# M2354 register map
File version: 1.0
Registers are 32-bit, read-write, reset 0x0 unless marked. A register's access mark holds for its fields unless they carry their own. Offsets are from the block's base; [hi:lo] are bit positions; {n}, {i} and the like mark numbered series; 'fields as' and 'values as' point back to an identical list.

## DPM_NS — SCU Register Map
Base 0x5002F600
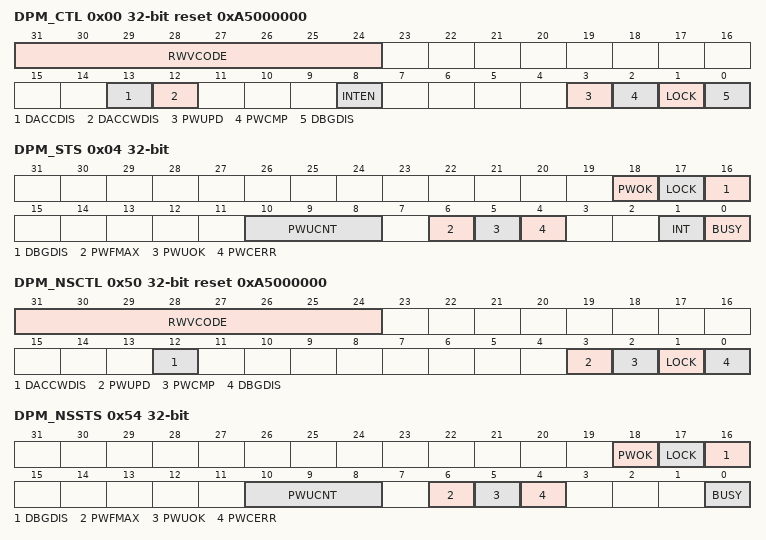
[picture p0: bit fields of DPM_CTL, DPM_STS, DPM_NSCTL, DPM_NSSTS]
0x00 DPM_CTL reset 0xA5000000 (reset mask 0xFFFFFFF0) — Secure DPM Control Register
  [31:24] RWVCODE — Write Verify Code and Read Verify Code. Read operation:
    90=The write verify code, 0x5A, is needed to do a valid write to DPM_CTL; 165=The read access for DPM_CTL is correct
  [13] DACCDIS — Debug Access Disable Bit. This bit disables the accessibility of external debugger to all DPM registers.
    0=External debugger can read/write DPM registers; 1=External debugger cannot read/write DPM registers
  [12] DACCWDIS — Secure DPM Debug Write Access Disable Bit. This bit disables the ability of external debugger to set Secure DPM registers for debug authentication.
    0=External debugger can set Secure DPM registers; 1=External debugger cannot set Secure DPM registers
  [8] INTEN — DPM Interrupt Enable Bit
    0=DPM interrupt function Enabled; 1=DPM interrupt function Disabled
  [3] PWUPD — Secure DPM Password Update Bit. Set to enter the process of updating Secure DPM password. Note 1: This bit should be set with PWCMP equal to 0. Note 2: This bit will be cleared after the update process is finished.
    0=No operation; 1=Update Secure DPM password
  [2] PWCMP — Secure DPM Password Compare Bit. Set to enter the process of compare Secure DPM password. Note: This bit will be cleared after the comparison process is finished.
    0=No operation; 1=Compare Secure DPM password
  [1] LOCK — Set Secure DPM Debug Lock Bit. When this bit is read as 0, it can be written to 1 to configure the Secure DPM LOCK bit (LOCKS). When written: Note: This bit can be set to 1 but cannot be cleared to 0.
    0=No operation; 1=Trigger the process to set LOCKS configuration bit
  [0] DBGDIS — Set Secure DPM Debug Disable Bit. When this bit is read as 0, it can be written to 1 to configure the Secure DPM DBGDIS bit (DBGDISS). When written: Note: This bit can be set to 1 but cannot be cleared to 0.
    0=No operation; 1=Trigger the process to set DBGDISS configuration bit
0x04 DPM_STS (reset mask 0xFFF0F0FF) — Secure DPM Status Register
  [18] PWOK ro — Secure Password OK Flag (Read Only). This bit indicates the Secure DPM password has been checked and is correct.
    0=The Secure DPM password has not been checked pass, yet; 1=The Secure DPM password has been checked pass since last cold reset
  [17] LOCK ro — Secure Debug Lock Flag (Read Only). This bit indicates the current value of LOCKS bit.
  [16] DBGDIS ro — Secure Debug Disable Flag (Read Only). This bit indicates the current value of DBGDISS bit. {PWOK, LOCK, DBGDIS} bits define the current state of DPM.
    0=DEFAULT state. LOCKED state; 1=CLOSE state; 5=OPEN state
  [10:8] PWUCNT ro — Secure DPM Password Updated Times (Read Only). This bit indicates how many times of secure password has been updated. The max value is 7. If PWUCNT reached the max value, Secure DPM password cannot be updated anymore.
  [6] PWFMAX ro — Secure DPM Password Fail Times Maximum Reached Flag (Read Only). This bit indicates if the fail times of comparing Secure DPM password reached max times.
    0=Max time has not reached and Secure DPM password comparison can be triggered; 1=Max time reached and Secure DPM password comparison cannot be processed anymore
  [5] PWUOK — Secure DPM Password Updated Flag. This bit indicates Secure DPM password has been updated successfully. When read: Note: This flag is write-one-clear.
    0=No successful updating process has happened; 1=There is at least one successful updating process since last clearing of this bit
  [4] PWCERR — Secure DPM Password Compared Error Flag. This bit indicates the result of Secure DPM password comparison. When read: Note: This flag is write-one-clear.
    0=The result of Secure DPM password is correct; 1=The result of Secure DPM password is incorrect
  [1] INT ro — DPM Interrupt Flag (Read Only). This bit indicates the interrupt is triggered. Note: This bit is cleared automatically when PWCERR flag in both DPM_STS and DPM_NSSTS are 0.
    0=Interrupt is not enabled or no password comparison flag is set; 1=Interrupt is enabled and PWCERR flag in either DPM_STS or DPM_NSSTS register is not cleared
  [0] BUSY ro — DPM Busy Flag (Read Only). This bit indicates the DPM is busy.
    0=DPM is not busy and writing to any register is accepted; 1=DPM is busy and other bits in DPM_STS register are not valid and writing to any register is ignored
{0x10+4i} DPM_SPW{i} wo reset 0xFFFFFFFF (i=0..3) — Secure DPM Password {i}
  [31:0] PW — Password. Write password[{32i+31}:{32i}] to this register to update or compare Secure DPM password. It is write-only and always read as 0xFFFFFFFF.
0x50 DPM_NSCTL reset 0xA5000000 (reset mask 0xFFFFFFF0) — Non-secure DPM Control Register
  [31:24] RWVCODE — Write Verify Code and Read Verify Code. Read operation:
    90=The write verify code, 0x5A, is needed to do a valid write to DPM_NSCTL; 165=The read access for DPM_NSCTL is correct
  [12] DACCWDIS — Debug Write Access Disable Bit. This bit disables the ability of external debugger to set Non-secure DPM registers for debug authentication.
    0=External debugger can set Non-secure DPM registers; 1=External debugger cannot set Non-secure DPM registers
  [3] PWUPD — Non-secure DPM Password Update Bit. Set to enter the process of updating Non-secure DPM password. Note 1: This bit should be set with PWCMP equal to 0. Note 2: This bit will be cleared after the update process is finished.
    0=No operation; 1=Update Non-secure DPM password
  [2] PWCMP — Non-secure DPM Password Compare Bit. Set to enter the process of compare Non-secure DPM password. Note: This bit will be cleared after the comparison process is finished.
    0=No operation; 1=Compare Non-secure DPM password
  [1] LOCK — Set Non-secure DPM Debug Lock Bit. When this bit is read as 0, it can be written to 1 to configure the Non-secure DPM LOCK bit (LOCKNS). When written: Note: This bit can be set to 1 but cannot be cleared to 0.
    0=No operation; 1=Trigger the process to set LOCKNS configuration bit
  [0] DBGDIS — Set Non-secure DPM Debug Disable Bit. When this bit is read as 0, it can be written to 1 to configure the Non-secure DPM DBGDIS bit (DBGDISNS). When written: Note: This bit can be set to 1 but cannot be cleared to 0.
    0=No operation; 1=Trigger the process to set DBGDISNS configuration bit
0x54 DPM_NSSTS (reset mask 0xFFF0F0FF) — Non-secure DPM Status Register
  [18] PWOK ro — Non-secure Password OK Flag (Read Only). This bit indicates the Non-secure DPM password has been checked and is correct.
    0=The Non-secure DPM password has not been checked pass, yet; 1=The Non-secure DPM password has been checked pass since last cold reset
  [17] LOCK ro — Non-secure Debug Lock Flag (Read Only). This bit indicates the current value of LOCKNS bit.
  [16] DBGDIS ro — Non-secure Debug Disable Flag (Read Only). This bit indicates the current value of DBGDISNS bit. {PWOK, LOCK, DBGDIS} bits define the current state of DPM.
    0=DEFAULT state. LOCKED state; 1=CLOSE state; 5=OPEN state
  [10:8] PWUCNT ro — Non-secure DPM Password Updated Times (Read Only). This bit indicates how many times of non-secure password has been updated. The max value is 7. If PWUCNT reached the max value, Non-secure DPM password cannot be updated anymore.
  [6] PWFMAX ro — Non-secure DPM Password Fail Times Maximum Reached Flag (Read Only). This bit indicates if the fail times of comparing Non-secure DPM password reached max times.
    0=Max time has not reached and Non-secure DPM password comparison can be triggered; 1=Max time reached and Non-secure DPM password comparison cannot be processed anymore
  [5] PWUOK — Non-secure DPM Password Updated Flag. This bit indicates Non-secure DPM password has been updated correctly. When read: Note: This flag is write-one-clear.
    values as DPM_STS.PWUOK
  [4] PWCERR — Non-secure DPM Password Compared Error Flag. This bit indicates the result of Non-secure DPM password comparison. Note: This flag is write-one-clear.
    0=The result of Non-secure DPM password is correct; 1=The result of Non-secure DPM password is incorrect
  [0] BUSY ro — DPM Busy Flag (Read Only). This bit indicates the DPM is busy.
    0=DPM is not busy and writing to any register is accepted; 1=DPM is busy and other bits in DPM_NSSTS register are not valid and writing to any register is ignored
{0x60+4i} DPM_NSPW{i} wo reset 0xFFFFFFFF (i=0..3) — Non-secure DPM Password {i}
  [31:0] PW — Password. Write password[{32i+31}:{32i}] to this register to update or compare Non-secure DPM password. It is write-only and always read as 0xFFFFFFFF.
